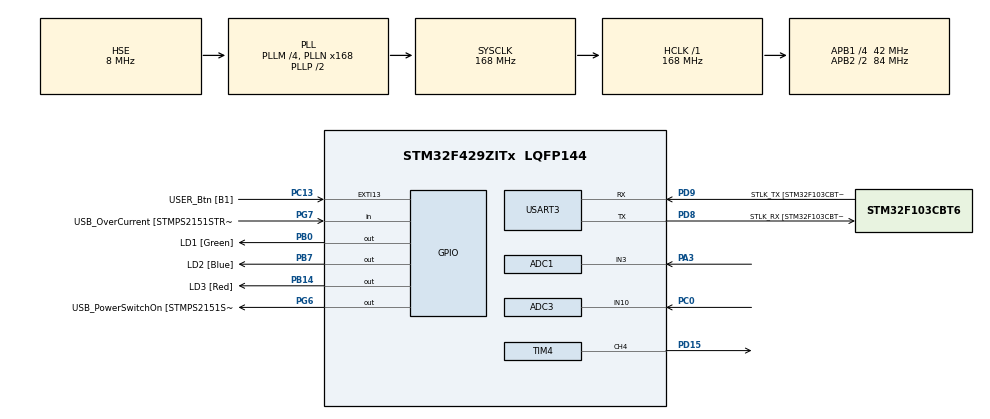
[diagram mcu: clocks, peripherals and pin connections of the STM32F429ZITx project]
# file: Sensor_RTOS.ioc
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ADC1.Channel-0\#ChannelRegularConversion=ADC_CHANNEL_3
ADC1.NbrOfConversionFlag=1
ADC1.Rank-0\#ChannelRegularConversion=1
ADC1.SamplingTime-0\#ChannelRegularConversion=ADC_SAMPLETIME_3CYCLES
ADC1.master=1
ADC3.Channel-0\#ChannelRegularConversion=ADC_CHANNEL_10
ADC3.NbrOfConversionFlag=1
ADC3.Rank-0\#ChannelRegularConversion=1
ADC3.SamplingTime-0\#ChannelRegularConversion=ADC_SAMPLETIME_3CYCLES
FREERTOS.Tasks01=defaultTask,0,128,StartDefaultTask,Default,NULL,Dynamic,NULL,NULL;thermistorTask0,-2,128,ThermistorTask02,Default,NULL,Dynamic,NULL,NULL;gasTask03,2,128,GasTask03,Default,NULL,Dynamic,NULL,NULL
Mcu.Family=STM32F4
Mcu.Name=STM32F429ZITx
Mcu.Package=LQFP144
NVIC.ADC_IRQn=true\:5\:0\:false\:false\:true\:true\:true\:true\:true
NVIC.PriorityGroup=NVIC_PRIORITYGROUP_4
NVIC.TIM4_IRQn=true\:5\:0\:false\:false\:true\:true\:true\:true\:true
PA13.GPIO_Label=TMS
PA13.Mode=Serial_Wire
PA13.Signal=SYS_JTMS-SWDIO
PA14.GPIO_Label=TCK
PA14.Mode=Serial_Wire
PA14.Signal=SYS_JTCK-SWCLK
PA3.Signal=ADCx_IN3
PB0.GPIO_Label=LD1 [Green]
PB0.Signal=GPIO_Output
PB14.GPIO_Label=LD3 [Red]
PB14.Signal=GPIO_Output
PB7.GPIO_Label=LD2 [Blue]
PB7.Signal=GPIO_Output
PC0.Signal=ADCx_IN10
PC13.GPIO_Label=USER_Btn [B1]
PC13.Signal=GPXTI13
PC14/OSC32_IN.Mode=LSE-External-Oscillator
PC14/OSC32_IN.Signal=RCC_OSC32_IN
PC15/OSC32_OUT.Mode=LSE-External-Oscillator
PC15/OSC32_OUT.Signal=RCC_OSC32_OUT
PD15.Signal=S_TIM4_CH4
PD8.GPIO_Label=STLK_RX [STM32F103CBT6_PA3]
PD8.Mode=Asynchronous
PD8.Signal=USART3_TX
PD9.GPIO_Label=STLK_TX [STM32F103CBT6_PA2]
PD9.Mode=Asynchronous
PD9.Signal=USART3_RX
PG6.GPIO_Label=USB_PowerSwitchOn [STMPS2151STR_EN]
PG6.Signal=GPIO_Output
PG7.GPIO_Label=USB_OverCurrent [STMPS2151STR_FAULT]
PG7.Signal=GPIO_Input
PH0/OSC_IN.GPIO_Label=MCO [STM32F103CBT6_PA8]
PH0/OSC_IN.Mode=HSE-External-Clock-Source
PH0/OSC_IN.Signal=RCC_OSC_IN
PH1/OSC_OUT.Mode=HSE-External-Clock-Source
PH1/OSC_OUT.Signal=RCC_OSC_OUT
ProjectManager.HeapSize=0x200
ProjectManager.StackSize=0x400
ProjectManager.TargetToolchain=STM32CubeIDE
RCC.48MHZClocksFreq_Value=48000000
RCC.AHBFreq_Value=168000000
RCC.APB1CLKDivider=RCC_HCLK_DIV4
RCC.APB1Freq_Value=42000000
RCC.APB1TimFreq_Value=84000000
RCC.APB2CLKDivider=RCC_HCLK_DIV2
RCC.APB2Freq_Value=84000000
RCC.APB2TimCLKDivider=2
RCC.APB2TimFreq_Value=168000000
RCC.CortexFreq_Value=168000000
RCC.HCLKFreq_Value=168000000
RCC.HSE_VALUE=8000000
RCC.HSI_VALUE=16000000
RCC.PLLM=4
RCC.PLLMUL=RCC_PLL_MUL9
RCC.PLLN=168
RCC.PLLQ=7
RCC.PLLSourceVirtual=RCC_PLLSOURCE_HSE
RCC.PRESCALERUSB=RCC_USBCLKSOURCE_PLL_DIV1_5
RCC.SYSCLKFreq_VALUE=168000000
RCC.SYSCLKSource=RCC_SYSCLKSOURCE_PLLCLK
RCC.SYSCLKSourceVirtual=RCC_SYSCLKSOURCE_PLLCLK
RCC.USBFreq_Value=48000000
RCC.VCOOutputFreq_Value=336000000
SH.ADCx_IN10.0=ADC3_IN10,IN10
SH.ADCx_IN3.0=ADC1_IN3,IN3
SH.S_TIM4_CH4.0=TIM4_CH4,PWM Generation4 CH4
TIM4.Channel-PWM\ Generation4\ CH4=TIM_CHANNEL_4
TIM4.Period=1000-1
TIM4.Prescaler=1680-1
USART3.VirtualMode=VM_ASYNC
VP_FREERTOS_VS_CMSIS_V1.Mode=CMSIS_V1
board=NUCLEO-F429ZI

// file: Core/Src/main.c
/* USER CODE BEGIN Header */
/**
  ******************************************************************************
  * @file           : main.c
  * @brief          : Main program body
  ******************************************************************************
  * @attention
  *
  * Copyright (c) 2023 STMicroelectronics.
  * All rights reserved.
  *
  * This software is licensed under terms that can be found in the LICENSE file
  * in the root directory of this software component.
  * If no LICENSE file comes with this software, it is provided AS-IS.
  *
  ******************************************************************************
  */
/* USER CODE END Header */
#include "main.h"
#include "cmsis_os.h"

/* USER CODE BEGIN PD */
  char uart[100];
  uint16_t thermistor;
  uint16_t gas;

/* USER CODE END PD */

ADC_HandleTypeDef hadc1;
ADC_HandleTypeDef hadc3;

TIM_HandleTypeDef htim4;

UART_HandleTypeDef huart3;

osThreadId defaultTaskHandle;
osThreadId thermistorTask0Handle;
osThreadId gasTask03Handle;

void SystemClock_Config(void);
static void MX_GPIO_Init(void);
static void MX_USART3_UART_Init(void);
static void MX_ADC1_Init(void);
static void MX_TIM4_Init(void);
static void MX_ADC3_Init(void);
void StartDefaultTask(void const * argument);
void ThermistorTask02(void const * argument);
void GasTask03(void const * argument);

int main(void)
{

  /* MCU Configuration--------------------------------------------------------*/

  /* Reset of all peripherals, Initializes the Flash interface and the Systick. */
  HAL_Init();

  /* Configure the system clock */
  SystemClock_Config();

  /* Initialize all configured peripherals */
  MX_GPIO_Init();
  MX_USART3_UART_Init();
  MX_ADC1_Init();
  MX_TIM4_Init();
  MX_ADC3_Init();

  /* Create the thread(s) */
  /* definition and creation of defaultTask */
  osThreadDef(defaultTask, StartDefaultTask, osPriorityNormal, 0, 128);
  defaultTaskHandle = osThreadCreate(osThread(defaultTask), NULL);

  /* definition and creation of thermistorTask0 */
  osThreadDef(thermistorTask0, ThermistorTask02, osPriorityLow, 0, 128);
  thermistorTask0Handle = osThreadCreate(osThread(thermistorTask0), NULL);

  /* definition and creation of gasTask03 */
  osThreadDef(gasTask03, GasTask03, osPriorityHigh, 0, 128);
  gasTask03Handle = osThreadCreate(osThread(gasTask03), NULL);

  /* Start scheduler */
  osKernelStart();
  /* We should never get here as control is now taken by the scheduler */
  /* Infinite loop */
  while (1)
  {

  }
}

void SystemClock_Config(void)
{
  RCC_OscInitTypeDef RCC_OscInitStruct = {0};
  RCC_ClkInitTypeDef RCC_ClkInitStruct = {0};

  /** Configure the main internal regulator output voltage
  */
  __HAL_RCC_PWR_CLK_ENABLE();
  __HAL_PWR_VOLTAGESCALING_CONFIG(PWR_REGULATOR_VOLTAGE_SCALE1);

  /** Initializes the RCC Oscillators according to the specified parameters
  * in the RCC_OscInitTypeDef structure.
  */
  RCC_OscInitStruct.OscillatorType = RCC_OSCILLATORTYPE_HSE;
  RCC_OscInitStruct.HSEState = RCC_HSE_BYPASS;
  RCC_OscInitStruct.PLL.PLLState = RCC_PLL_ON;
  RCC_OscInitStruct.PLL.PLLSource = RCC_PLLSOURCE_HSE;
  RCC_OscInitStruct.PLL.PLLM = 4;
  RCC_OscInitStruct.PLL.PLLN = 168;
  RCC_OscInitStruct.PLL.PLLP = RCC_PLLP_DIV2;
  RCC_OscInitStruct.PLL.PLLQ = 7;
  if (HAL_RCC_OscConfig(&RCC_OscInitStruct) != HAL_OK)
  {
    Error_Handler();
  }

  /** Initializes the CPU, AHB and APB buses clocks
  */
  RCC_ClkInitStruct.ClockType = RCC_CLOCKTYPE_HCLK|RCC_CLOCKTYPE_SYSCLK
                              |RCC_CLOCKTYPE_PCLK1|RCC_CLOCKTYPE_PCLK2;
  RCC_ClkInitStruct.SYSCLKSource = RCC_SYSCLKSOURCE_PLLCLK;
  RCC_ClkInitStruct.AHBCLKDivider = RCC_SYSCLK_DIV1;
  RCC_ClkInitStruct.APB1CLKDivider = RCC_HCLK_DIV4;
  RCC_ClkInitStruct.APB2CLKDivider = RCC_HCLK_DIV2;

  if (HAL_RCC_ClockConfig(&RCC_ClkInitStruct, FLASH_LATENCY_5) != HAL_OK)
  {
    Error_Handler();
  }
}

static void MX_ADC1_Init(void)
{

  ADC_ChannelConfTypeDef sConfig = {0};

  /** Configure the global features of the ADC (Clock, Resolution, Data Alignment and number of conversion)
  */
  hadc1.Instance = ADC1;
  hadc1.Init.ClockPrescaler = ADC_CLOCK_SYNC_PCLK_DIV4;
  hadc1.Init.Resolution = ADC_RESOLUTION_12B;
  hadc1.Init.ScanConvMode = DISABLE;
  hadc1.Init.ContinuousConvMode = DISABLE;
  hadc1.Init.DiscontinuousConvMode = DISABLE;
  hadc1.Init.ExternalTrigConvEdge = ADC_EXTERNALTRIGCONVEDGE_NONE;
  hadc1.Init.ExternalTrigConv = ADC_SOFTWARE_START;
  hadc1.Init.DataAlign = ADC_DATAALIGN_RIGHT;
  hadc1.Init.NbrOfConversion = 1;
  hadc1.Init.DMAContinuousRequests = DISABLE;
  hadc1.Init.EOCSelection = ADC_EOC_SINGLE_CONV;
  if (HAL_ADC_Init(&hadc1) != HAL_OK)
  {
    Error_Handler();
  }

  /** Configure for the selected ADC regular channel its corresponding rank in the sequencer and its sample time.
  */
  sConfig.Channel = ADC_CHANNEL_3;
  sConfig.Rank = 1;
  sConfig.SamplingTime = ADC_SAMPLETIME_3CYCLES;
  if (HAL_ADC_ConfigChannel(&hadc1, &sConfig) != HAL_OK)
  {
    Error_Handler();
  }

}

static void MX_ADC3_Init(void)
{

  ADC_ChannelConfTypeDef sConfig = {0};

  /** Configure the global features of the ADC (Clock, Resolution, Data Alignment and number of conversion)
  */
  hadc3.Instance = ADC3;
  hadc3.Init.ClockPrescaler = ADC_CLOCK_SYNC_PCLK_DIV4;
  hadc3.Init.Resolution = ADC_RESOLUTION_12B;
  hadc3.Init.ScanConvMode = DISABLE;
  hadc3.Init.ContinuousConvMode = DISABLE;
  hadc3.Init.DiscontinuousConvMode = DISABLE;
  hadc3.Init.ExternalTrigConvEdge = ADC_EXTERNALTRIGCONVEDGE_NONE;
  hadc3.Init.ExternalTrigConv = ADC_SOFTWARE_START;
  hadc3.Init.DataAlign = ADC_DATAALIGN_RIGHT;
  hadc3.Init.NbrOfConversion = 1;
  hadc3.Init.DMAContinuousRequests = DISABLE;
  hadc3.Init.EOCSelection = ADC_EOC_SINGLE_CONV;
  if (HAL_ADC_Init(&hadc3) != HAL_OK)
  {
    Error_Handler();
  }

  /** Configure for the selected ADC regular channel its corresponding rank in the sequencer and its sample time.
  */
  sConfig.Channel = ADC_CHANNEL_10;
  sConfig.Rank = 1;
  sConfig.SamplingTime = ADC_SAMPLETIME_3CYCLES;
  if (HAL_ADC_ConfigChannel(&hadc3, &sConfig) != HAL_OK)
  {
    Error_Handler();
  }

}

static void MX_TIM4_Init(void)
{

  TIM_MasterConfigTypeDef sMasterConfig = {0};
  TIM_OC_InitTypeDef sConfigOC = {0};

  htim4.Instance = TIM4;
  htim4.Init.Prescaler = 1680-1;
  htim4.Init.CounterMode = TIM_COUNTERMODE_UP;
  htim4.Init.Period = 1000-1;
  htim4.Init.ClockDivision = TIM_CLOCKDIVISION_DIV1;
  htim4.Init.AutoReloadPreload = TIM_AUTORELOAD_PRELOAD_DISABLE;
  if (HAL_TIM_PWM_Init(&htim4) != HAL_OK)
  {
    Error_Handler();
  }
  sMasterConfig.MasterOutputTrigger = TIM_TRGO_RESET;
  sMasterConfig.MasterSlaveMode = TIM_MASTERSLAVEMODE_DISABLE;
  if (HAL_TIMEx_MasterConfigSynchronization(&htim4, &sMasterConfig) != HAL_OK)
  {
    Error_Handler();
  }
  sConfigOC.OCMode = TIM_OCMODE_PWM1;
  sConfigOC.Pulse = 0;
  sConfigOC.OCPolarity = TIM_OCPOLARITY_HIGH;
  sConfigOC.OCFastMode = TIM_OCFAST_DISABLE;
  if (HAL_TIM_PWM_ConfigChannel(&htim4, &sConfigOC, TIM_CHANNEL_4) != HAL_OK)
  {
    Error_Handler();
  }
  HAL_TIM_MspPostInit(&htim4);

}

static void MX_USART3_UART_Init(void)
{

  huart3.Instance = USART3;
  huart3.Init.BaudRate = 115200;
  huart3.Init.WordLength = UART_WORDLENGTH_8B;
  huart3.Init.StopBits = UART_STOPBITS_1;
  huart3.Init.Parity = UART_PARITY_NONE;
  huart3.Init.Mode = UART_MODE_TX_RX;
  huart3.Init.HwFlowCtl = UART_HWCONTROL_NONE;
  huart3.Init.OverSampling = UART_OVERSAMPLING_16;
  if (HAL_UART_Init(&huart3) != HAL_OK)
  {
    Error_Handler();
  }

}

static void MX_GPIO_Init(void)
{
  GPIO_InitTypeDef GPIO_InitStruct = {0};

  /* GPIO Ports Clock Enable */
  __HAL_RCC_GPIOC_CLK_ENABLE();
  __HAL_RCC_GPIOH_CLK_ENABLE();
  __HAL_RCC_GPIOA_CLK_ENABLE();
  __HAL_RCC_GPIOB_CLK_ENABLE();
  __HAL_RCC_GPIOD_CLK_ENABLE();
  __HAL_RCC_GPIOG_CLK_ENABLE();

  /*Configure GPIO pin Output Level */
  HAL_GPIO_WritePin(GPIOB, LD1_Pin|LD3_Pin|LD2_Pin, GPIO_PIN_RESET);

  /*Configure GPIO pin Output Level */
  HAL_GPIO_WritePin(USB_PowerSwitchOn_GPIO_Port, USB_PowerSwitchOn_Pin, GPIO_PIN_RESET);

  /*Configure GPIO pin : USER_Btn_Pin */
  GPIO_InitStruct.Pin = USER_Btn_Pin;
  GPIO_InitStruct.Mode = GPIO_MODE_IT_RISING;
  GPIO_InitStruct.Pull = GPIO_NOPULL;
  HAL_GPIO_Init(USER_Btn_GPIO_Port, &GPIO_InitStruct);

  /*Configure GPIO pins : LD1_Pin LD3_Pin LD2_Pin */
  GPIO_InitStruct.Pin = LD1_Pin|LD3_Pin|LD2_Pin;
  GPIO_InitStruct.Mode = GPIO_MODE_OUTPUT_PP;
  GPIO_InitStruct.Pull = GPIO_NOPULL;
  GPIO_InitStruct.Speed = GPIO_SPEED_FREQ_LOW;
  HAL_GPIO_Init(GPIOB, &GPIO_InitStruct);

  /*Configure GPIO pin : USB_PowerSwitchOn_Pin */
  GPIO_InitStruct.Pin = USB_PowerSwitchOn_Pin;
  GPIO_InitStruct.Mode = GPIO_MODE_OUTPUT_PP;
  GPIO_InitStruct.Pull = GPIO_NOPULL;
  GPIO_InitStruct.Speed = GPIO_SPEED_FREQ_LOW;
  HAL_GPIO_Init(USB_PowerSwitchOn_GPIO_Port, &GPIO_InitStruct);

  /*Configure GPIO pin : USB_OverCurrent_Pin */
  GPIO_InitStruct.Pin = USB_OverCurrent_Pin;
  GPIO_InitStruct.Mode = GPIO_MODE_INPUT;
  GPIO_InitStruct.Pull = GPIO_NOPULL;
  HAL_GPIO_Init(USB_OverCurrent_GPIO_Port, &GPIO_InitStruct);

}

void StartDefaultTask(void const * argument)
{
  for(;;)
  {
    osDelay(1);
  }
}

void ThermistorTask02(void const * argument)
{
  /* USER CODE BEGIN ThermistorTask02 */
	 memset(uart,0,sizeof(uart));

  /* Infinite loop */
  for(;;)
  {
	  int value = thermistor*0.029;
      //thermistor temperature = resolution * 0.029//
	  HAL_ADC_Start_IT(&hadc1);

	  sprintf(uart,"%d°C\r\n",value);
	  HAL_UART_Transmit(&huart3,uart,sizeof(uart),0xFFFF);
    osDelay(1000);
  }
  /* USER CODE END ThermistorTask02 */
}

void GasTask03(void const * argument)
{
  /* USER CODE BEGIN GasTask03 */
	memset(uart,0,sizeof(uart));
  /* Infinite loop */
  for(;;)
  {
	  HAL_ADC_Start_IT(&hadc3);
	 	  sprintf(uart,"%d\r\n",gas);
	 	  HAL_UART_Transmit(&huart3,uart,sizeof(uart),0xFFFF);
	     osDelay(1000);
  }
  /* USER CODE END GasTask03 */
}
void HAL_ADC_ConvCpltCallback(ADC_HandleTypeDef* hadc)
{
    thermistor = HAL_ADC_GetValue(&hadc1);
    gas = HAL_ADC_GetValue(&hadc3);
}

void Error_Handler(void)
{
  __disable_irq();
  while (1)
  {
  }
}
